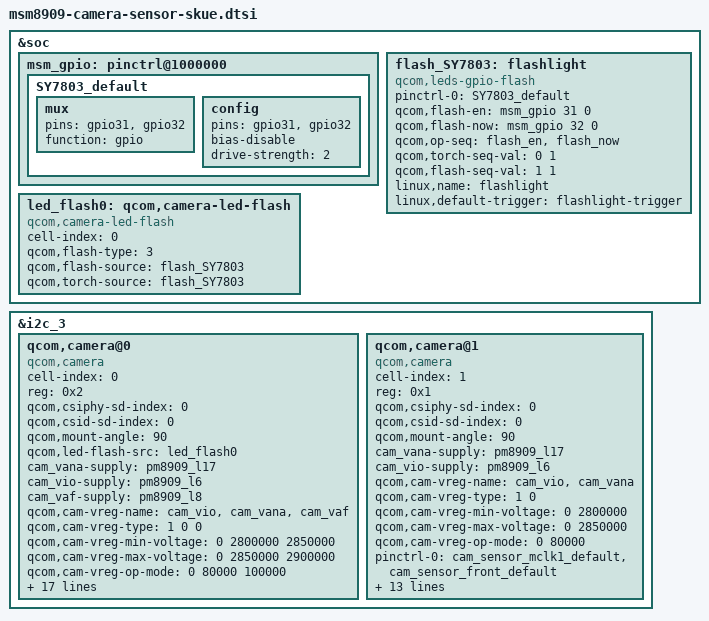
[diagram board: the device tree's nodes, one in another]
/*
 * Copyright (c) 2017-18 The Linux Foundation. All rights reserved.
 *
 * This program is free software; you can redistribute it and/or modify
 * it under the terms of the GNU General Public License version 2 and
 * only version 2 as published by the Free Software Foundation.
 *
 * This program is distributed in the hope that it will be useful,
 * but WITHOUT ANY WARRANTY; without even the implied warranty of
 * MERCHANTABILITY or FITNESS FOR A PARTICULAR PURPOSE.  See the
 * GNU General Public License for more details.
 */
&soc {

	msm_gpio: pinctrl@1000000 {
		SY7803_default: SY7803_default {
			mux {
				/* CLK, DATA */
				pins = "gpio31", "gpio32";
				function = "gpio";
			};

			config {
				pins = "gpio31", "gpio32";
				bias-disable; /* No PULL */
				drive-strength = <2>; /* 2 MA */
			};
		};
	};

	flash_SY7803:flashlight {
		compatible = "qcom,leds-gpio-flash";
		status = "okay";
		pinctrl-names = "flash_default";
		pinctrl-0 = <&SY7803_default>;
		qcom,flash-en = <&msm_gpio 31 0>;
		qcom,flash-now = <&msm_gpio 32 0>;
		qcom,op-seq = "flash_en", "flash_now";
		qcom,torch-seq-val = <0 1>;
		qcom,flash-seq-val = <1 1>;
		linux,name = "flashlight";
		linux,default-trigger = "flashlight-trigger";
	};

	led_flash0: qcom,camera-led-flash {
		cell-index = <0>;
		compatible = "qcom,camera-led-flash";
		qcom,flash-type = <3>;
		qcom,flash-source = <&flash_SY7803>;
		qcom,torch-source = <&flash_SY7803>;
	};
};

&i2c_3 {

	qcom,camera@0 {
		cell-index = <0>;
		compatible = "qcom,camera";
		reg = <0x2>;
		qcom,csiphy-sd-index = <0>;
		qcom,csid-sd-index = <0>;
		qcom,mount-angle = <90>;
		qcom,led-flash-src = <&led_flash0>;
		cam_vana-supply = <&pm8909_l17>;
		cam_vio-supply = <&pm8909_l6>;
		cam_vaf-supply = <&pm8909_l8>;
		qcom,cam-vreg-name = "cam_vio", "cam_vana",
			"cam_vaf";
		qcom,cam-vreg-type = <1 0 0>;
		qcom,cam-vreg-min-voltage = <0 2800000 2850000>;
		qcom,cam-vreg-max-voltage = <0 2850000 2900000>;
		qcom,cam-vreg-op-mode = <0 80000 100000>;
		pinctrl-names = "cam_default", "cam_suspend";
		pinctrl-0 = <&cam_sensor_mclk0_default
			&cam_sensor_rear_default>;
		pinctrl-1 = <&cam_sensor_mclk0_sleep &cam_sensor_rear_sleep>;
		gpios = <&msm_gpio 26 0>,
			<&msm_gpio 35 0>,
			<&msm_gpio 34 0>;
		qcom,gpio-reset = <1>;
		qcom,gpio-standby = <2>;
		qcom,gpio-req-tbl-num = <0 1 2>;
		qcom,gpio-req-tbl-flags = <1 0 0>;
		qcom,gpio-req-tbl-label = "CAMIF_MCLK",
			"CAM_RESET1",
			"CAM_STANDBY";
		qcom,sensor-position = <0>;
		qcom,sensor-mode = <0>;
		qcom,cci-master = <0>;
		status = "ok";
		clocks = <&clock_gcc clk_mclk0_clk_src>,
			<&clock_gcc clk_gcc_camss_mclk0_clk>;
		clock-names = "cam_src_clk", "cam_clk";
		qcom,clock-rates = <24000000 0>;
	};

	qcom,camera@1 {
		cell-index = <1>;
		compatible = "qcom,camera";
		reg = <0x1>;
		qcom,csiphy-sd-index = <0>;
		qcom,csid-sd-index = <0>;
		qcom,mount-angle = <90>;
		cam_vana-supply = <&pm8909_l17>;
		cam_vio-supply = <&pm8909_l6>;
		qcom,cam-vreg-name = "cam_vio", "cam_vana";
		qcom,cam-vreg-type = <1 0>;
		qcom,cam-vreg-min-voltage = <0 2800000>;
		qcom,cam-vreg-max-voltage = <0 2850000>;
		qcom,cam-vreg-op-mode = <0 80000>;
		pinctrl-names = "cam_default", "cam_suspend";
		pinctrl-0 = <&cam_sensor_mclk1_default
				&cam_sensor_front_default>;
		pinctrl-1 = <&cam_sensor_mclk1_sleep &cam_sensor_front_sleep>;
		gpios = <&msm_gpio 27 0>,
			<&msm_gpio 28 0>,
			<&msm_gpio 33 0>;
		qcom,gpio-reset = <1>;
		qcom,gpio-standby = <2>;
		qcom,gpio-req-tbl-num = <0 1 2>;
		qcom,gpio-req-tbl-flags = <1 0 0>;
		qcom,gpio-req-tbl-label = "CAMIF_MCLK",
			"CAM_RESET",
			"CAM_STANDBY";
		qcom,cci-master = <0>;
		status = "ok";
		clocks = <&clock_gcc clk_mclk1_clk_src>,
			<&clock_gcc clk_gcc_camss_mclk1_clk>;
		clock-names = "cam_src_clk", "cam_clk";
		qcom,clock-rates = <24000000 0>;
	};
};
